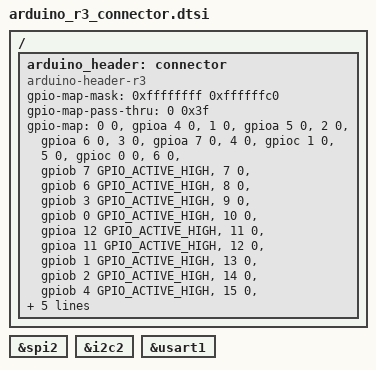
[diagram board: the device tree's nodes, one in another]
/*
 * Copyright (c) 2025 Arduino SA
 *
 * SPDX-License-Identifier: Apache-2.0
 */

/ {
	arduino_header: connector {
		compatible = "arduino-header-r3";
		#gpio-cells = <2>;
		gpio-map-mask = <0xffffffff 0xffffffc0>;
		gpio-map-pass-thru = <0 0x3f>;
		gpio-map = <0 0 &gpioa 4 0>, /* A0 */
			   <1 0 &gpioa 5 0>, /* A1 */
			   <2 0 &gpioa 6 0>, /* A2 */
			   <3 0 &gpioa 7 0>, /* A3 */
			   <4 0 &gpioc 1 0>, /* A4 */
			   <5 0 &gpioc 0 0>, /* A5 */
			   <6 0 &gpiob 7 GPIO_ACTIVE_HIGH>, /* D0 */
			   <7 0 &gpiob 6 GPIO_ACTIVE_HIGH>, /* D1 */
			   <8 0 &gpiob 3 GPIO_ACTIVE_HIGH>, /* D2 */
			   <9 0 &gpiob 0 GPIO_ACTIVE_HIGH>, /* D3 */
			   <10 0 &gpioa 12 GPIO_ACTIVE_HIGH>, /* D4 */
			   <11 0 &gpioa 11 GPIO_ACTIVE_HIGH>, /* D5 */
			   <12 0 &gpiob 1 GPIO_ACTIVE_HIGH>, /* D6 */
			   <13 0 &gpiob 2 GPIO_ACTIVE_HIGH>, /* D7 */
			   <14 0 &gpiob 4 GPIO_ACTIVE_HIGH>, /* D8 */
			   <15 0 &gpiob 8 GPIO_ACTIVE_HIGH>, /* D9 */
			   <16 0 &gpiob 9 GPIO_ACTIVE_HIGH>, /* D10 */
			   <17 0 &gpiob 15 GPIO_ACTIVE_HIGH>, /* D11 */
			   <18 0 &gpiob 14 GPIO_ACTIVE_HIGH>, /* D12 */
			   <19 0 &gpiob 13 GPIO_ACTIVE_HIGH>; /* D13 */
	};
};

arduino_spi: &spi2 {};

arduino_i2c: &i2c2 {};

arduino_serial: &usart1 {};
